# STM32WB05 register map
File version: 0.3
CPU: CM0+ r0p0, little endian, MPU, no FPU, 4 interrupt priority bits
Registers are 32-bit, read-write, reset 0x0 unless marked. A register's access mark holds for its fields unless they carry their own. Offsets are from the block's base; [hi:lo] are bit positions; {n}, {i} and the like mark numbered series.

## SYSTEM_CTRL
Base 0x40000000
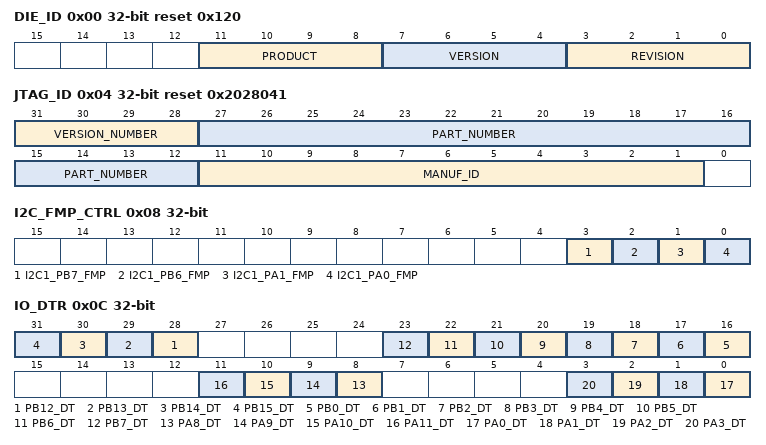
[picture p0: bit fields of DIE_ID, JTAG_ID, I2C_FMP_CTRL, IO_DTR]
0x00 DIE_ID ro reset 0x120
  [11:8] PRODUCT — Product version. May be used to discriminate several version of a same digital BLE LPH device embedding different analog versions
  [7:4] VERSION — Cut version
  [3:0] REVISION — Cut revision (metal fix)
0x04 JTAG_ID ro reset 0x2028041
  [31:28] VERSION_NUMBER — Version
  [27:12] PART_NUMBER
  [11:1] MANUF_ID — Manufacturer ID
0x08 I2C_FMP_CTRL
  [3] I2C1_PB7_FMP — I2C1 Fast-Mode Plus driving capability for I2C1_SDA on PB7 I/O. 0: PB7 pin operated in standard mode. 1: FM+ mode is enabled on PB7 pin, and speed control is bypassed
  [2] I2C1_PB6_FMP — I2C1 Fast-Mode Plus driving capability for I2C1_SCL on PB6 I/O. 0: PB6 pin operated in standard mode. 1: FM+ mode is enabled on PB6 pin, and speed control is bypassed.
  [1] I2C1_PA1_FMP — I2C1 Fast-Mode Plus driving capability for I2C1_SDA on PA1 I/O. 0: PA1 pin operated in standard mode. 1: FM+ mode is enabled on PA1 pin, and speed control is bypassed
  [0] I2C1_PA0_FMP — I2C1 Fast-Mode Plus driving capability for I2C1_SCL on PA0 I/O. 0: PA0 pin operated in standard mode. 1: FM+ mode is enabled on PA0 pin, and speed control is bypassed
0x0C IO_DTR
  [n+16] PB{n}_DT (n=12..15) — PB{n}_DT: Interrupt Detection Type for port B I/Os. 0: edge detection. 1: level detection.
  [n+16] PB{n}_DT (n=0..7) — PB{n}_DT: Interrupt Detection Type for port B I/Os. 0: edge detection. 1: level detection.
  [n] PA{n}_DT (n=8..11) — PA{n}_DT: Interrupt Detection Type for port A I/Os. 0: edge detection. 1: level detection.
  [n] PA{n}_DT (n=0..3) — PA{n}_DT: Interrupt Detection Type for port A I/Os. 0: edge detection. 1: level detection.
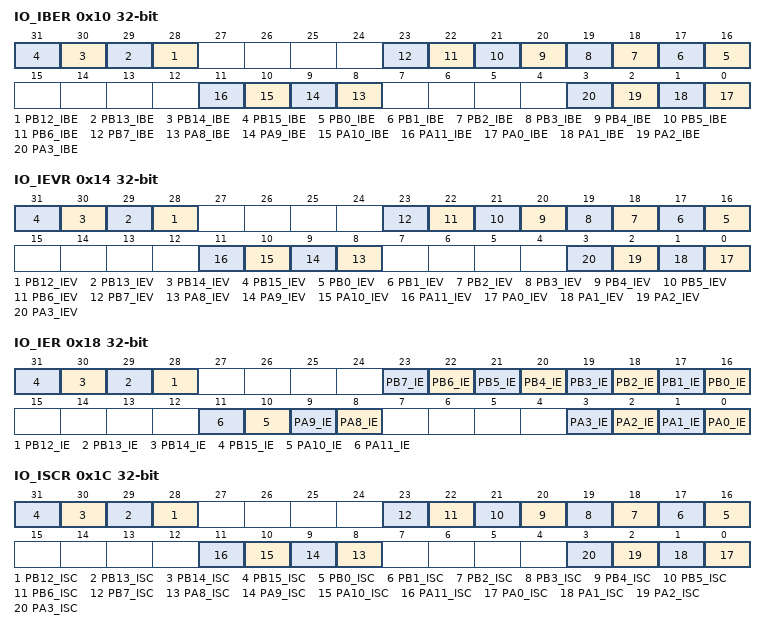
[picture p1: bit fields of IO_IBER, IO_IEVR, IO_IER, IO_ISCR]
0x10 IO_IBER
  [n+16] PB{n}_IBE (n=12..15) — PB{n}_IBE: Interrupt edge selection for port B I/Os. 0: single edge detection. 1: both edges detection.
  [n+16] PB{n}_IBE (n=0..7) — PB{n}_IBE: Interrupt edge selection for port B I/Os. 0: single edge detection. 1: both edges detection.
  [n] PA{n}_IBE (n=8..11) — PA{n}_IBE: Interrupt edge selection for Port A I/Os. 0: single edge detection. 1: both edges detection
  [n] PA{n}_IBE (n=0..3) — PA{n}_IBE: Interrupt edge selection for Port A I/Os. 0: single edge detection. 1: both edges detection
0x14 IO_IEVR
  [n+16] PB{n}_IEV (n=12..15) — PB{n}_IEV : Interrupt polarity event for Port B I/Os. 0: falling edge / low level. 1: rising edge / high level.
  [n+16] PB{n}_IEV (n=0..7) — PB{n}_IEV : Interrupt polarity event for Port B I/Os. 0: falling edge / low level. 1: rising edge / high level.
  [n] PA{n}_IEV (n=8..11) — PA{n}_IEV : Interrupt polarity event for Port A I/Os. 0: falling edge / low level. 1: rising edge / high level.
  [n] PA{n}_IEV (n=0..3) — PA{n}_IEV : Interrupt polarity event for Port A I/Os. 0: falling edge / low level. 1: rising edge / high level.
0x18 IO_IER
  [n+16] PB{n}_IE (n=12..15) — PB{n}_IE: Interrupt enable for port B I/Os. 0: interrupt is disabled. 1: interrupt is enabled.
  [n+16] PB{n}_IE (n=0..7) — PB{n}_IE: Interrupt enable for port B I/Os. 0: interrupt is disabled. 1: interrupt is enabled.
  [n] PA{n}_IE (n=8..11) — PA{n}_IE: Interrupt enable for port A I/Os. 0: interrupt is disabled. 1: interrupt is enabled.
  [n] PA{n}_IE (n=0..3) — PA{n}_IE: Interrupt enable for port A I/Os. 0: interrupt is disabled. 1: interrupt is enabled.
0x1C IO_ISCR
  [n+16] PB{n}_ISC (n=12..15) — PB{n}_ISC: Interrupt status (before mask) for port B I/Os. 0: no pending interrupt. 1: event occurred on corresponding I/O / interrupt occurred (if enabled). Cleared by writing 1 in the bit.
  [n+16] PB{n}_ISC (n=0..7) — PB{n}_ISC: Interrupt status (before mask) for port B I/Os. 0: no pending interrupt. 1: event occurred on corresponding I/O / interrupt occurred (if enabled). Cleared by writing 1 in the bit.
  [n] PA{n}_ISC (n=8..11) — PA{n}_ISC: Interrupt status (before mask) for port a I/Os. 0: no pending interrupt. 1: event occurred on corresponding I/O / interrupt occurred (if enabled). Cleared by writing 1 in the bit.
  [n] PA{n}_ISC (n=0..3) — PA{n}_ISC: Interrupt status (before mask) for port a I/Os. 0: no pending interrupt. 1: event occurred on corresponding I/O / interrupt occurred (if enabled). Cleared by writing 1 in the bit.
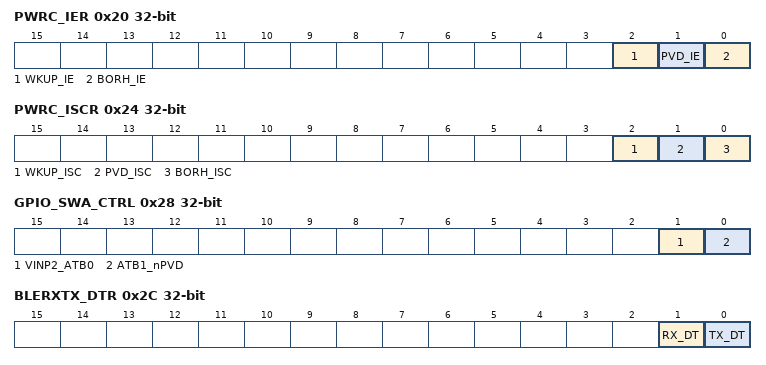
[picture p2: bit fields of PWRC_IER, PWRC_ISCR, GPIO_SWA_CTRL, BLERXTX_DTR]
0x20 PWRC_IER
  [2] WKUP_IE — WKUP_IE: Power Controller Wakeup event interrupt enable. 0: Interrupt on wakeup event seen by the PWRC is disabled. 1: Interrupt on wakeup event seen by the PWRC is enabled.
  [1] PVD_IE — PVD_IE: Programmable Voltage Detector interrupt enable. 0: PVD interrupt is disabled. 1: PVD interrupt is enabled.
  [0] BORH_IE — BORH_IE: BORH interrupt enable. 0: BORH interrupt is disabled. 1: BORH interrupt is enabled.
0x24 PWRC_ISCR
  [2] WKUP_ISC — WKUP_ISC: Indicates the Power Controller receives a Wakeup event. 0: no pending interrupt. 1: Wakeup event on PWRC occurred / interrupt occurred (if enabled). Cleared by writing 1 in the bit. This flag will be read at 1 if a wakeup event arrives so close to the low power mode entry requests that the PWRC aborts before shutting down the system.
  [1] PVD_ISC — PVD_ISC: Programmable Voltage Detector status. 0: no pending interrupt. 1: voltage went under programmed threshold / interrupt occurred (if enabled). Cleared by writing 1 in the bit.
  [0] BORH_ISC — BORH_ISC: BORH interrupt status. 0: no pending interrupt. 1: voltage went under BORH threshold / interrupt occurred (if enabled). Cleared by writing 1 in the bit.
0x28 GPIO_SWA_CTRL
  [1] VINP2_ATB0 — VINP2_ATB0: select the analog feature on PA3 between VINP2 and ATB0 when the PA3 I/O is programmed in analog mode (in the associated GPIO_MODER register): 0: VINP2 feature is selected (default). 1: ATB0 feature is selected
  [0] ATB1_nPVD — ATB1_nPVD: select the analog feature on PB14 between ATB1 and PVD when the PB14 I/O is programmed in analog mode (in the associated GPIO_MODER register): 0: PVD external voltage feature is selected (default). 1: ATB1 feature is selected
0x2C BLERXTX_DTR
  [1] RX_DT — RX_DT: detection type on RX_SEQUENCE signal: 0: detection on edge (default). 1: detection on level
  [0] TX_DT — TX_DT: detection type on TX_SEQUENCE signal: 0: detection on edge (default). 1: detection on level
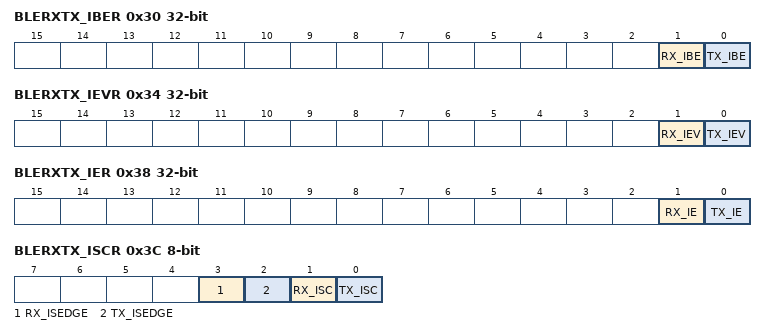
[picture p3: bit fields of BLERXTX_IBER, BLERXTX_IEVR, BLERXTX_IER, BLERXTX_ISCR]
0x30 BLERXTX_IBER
  [1] RX_IBE — RX_IBE: interrupt edge register on RX_SEQUENCE signal: 0: detection on single edge (default). 1: detection on both edges
  [0] TX_IBE — TX_IBE: interrupt edge register on TX_SEQUENCE signal: 0: detection on single edge (default). 1: detection on both edges
0x34 BLERXTX_IEVR
  [1] RX_IEV — RX_IEV: interrupt polarity event on RX_SEQUENCE signal: 0: detection on falling edge / low level (default). 1: detection on rising edge / high level
  [0] TX_IEV — TX_IEV: interrupt polarity event on TX_SEQUENCE signal: 0: detection on falling edge / low level (default). 1: detection on rising edge / high level
0x38 BLERXTX_IER
  [1] RX_IE — RX_IE: interrupt enable on RX_SEQUENCE signal: 0: RX_SEQUENCE interrupt is disabled (default). 1: RX_SEQUENCE interrupt is enabled
  [0] TX_IE — TX_IE: interrupt enable on TX_SEQUENCE signal: 0: TX_SEQUENCE interrupt is disabled (default). 1: TX_SEQUENCE interrupt is enabled
0x3C BLERXTX_ISCR 8-bit
  [3] RX_ISEDGE ro — RX_ISEDGE: interrupt edge status on RX_SEQUENCE signal: 0: falling edge on RX_SEQUENCE detected. 1: rising edge on RX_SEQUENCE detected.
  [2] TX_ISEDGE ro — TX_ISEDGE: interrupt edge status on TX_SEQUENCE signal: 0: falling edge on TX_SEQUENCE detected. 1: rising edge on TX_SEQUENCE detected.
  [1] RX_ISC — RX_ISC: interrupt status on RX_SEQUENCE signal (can be a rising or a falling edge depending on BLERXTX_IEVR and BLERXTX_IBER): 0: no activity on RX_SEQUENCE detected. 1: activity on RX_SEQUENCE occurred
  [0] TX_ISC — TX_ISC:interrupt status on TX_SEQUENCE signal (can be a rising or a falling edge depending on BLERXTX_IEVR and BLERXTX_IBER): 0: no activity on TX_SEQUENCE detected. 1: activity on TX_SEQUENCE occurred
